# CH583SFR register map
Vendor: WCH Ltd.; Series: CH58x; File version: 1.1
CPU: RISC-V r0p0, little endian, no MPU, no FPU, 2 interrupt priority bits
Registers are 8-bit, read-write, reset 0x0 unless marked. A register's access mark holds for its fields unless they carry their own. Offsets are from the block's base; [hi:lo] are bit positions; {n}, {i} and the like mark numbered series.

## SYS — System Control Register
Base 0x40001000
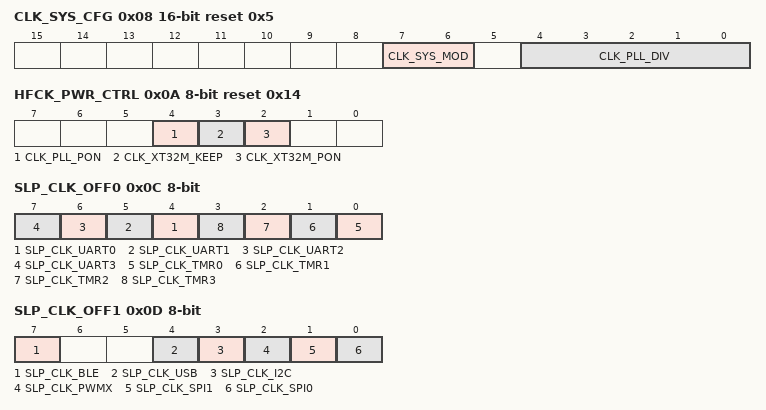
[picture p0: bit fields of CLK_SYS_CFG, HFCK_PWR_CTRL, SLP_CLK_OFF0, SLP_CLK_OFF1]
0x08 CLK_SYS_CFG 16-bit reset 0x5 — RWA, system clock configuration, SAM
  [7:6] CLK_SYS_MOD — RWA, system clock source mode: 00=divided from 32MHz, 01=divided from PLL-480MHz, 10=directly from 32MHz, 11=directly from 32KHz
  [4:0] CLK_PLL_DIV — RWA, output clock divider from PLL or CK32M
0x0A HFCK_PWR_CTRL reset 0x14 — RWA, high frequency clock module power control, SAM
  [4] CLK_PLL_PON — RWA, PLL power control: 0=power down, 1-power on
  [3] CLK_XT32M_KEEP — RWA, external 32MHz oscillator power keep under halt mode: 0=auto stop, 1=keep running
  [2] CLK_XT32M_PON — RWA, external 32MHz oscillator power control: 0=power down, 1-power on
0x0C SLP_CLK_OFF0 — RWA, sleep clock off control byte 0, SAM
  [n+4] SLP_CLK_UART{n} (n=0..3) — RWA, close UART{n} clock
  [n] SLP_CLK_TMR{n} (n=0..3) — RWA, close TMR{n} clock
0x0D SLP_CLK_OFF1 — RWA, sleep clock off control byte 1, SAM
  [7] SLP_CLK_BLE — RWA, close BLE clock
  [4] SLP_CLK_USB — RWA, close USB clock
  [3] SLP_CLK_I2C — RWA, close I2C clock
  [2] SLP_CLK_PWMX — RWA, close PWMx clock
  [1] SLP_CLK_SPI1 — RWA, close SPI1 clock
  [0] SLP_CLK_SPI0 — RWA, close SPI0 clock
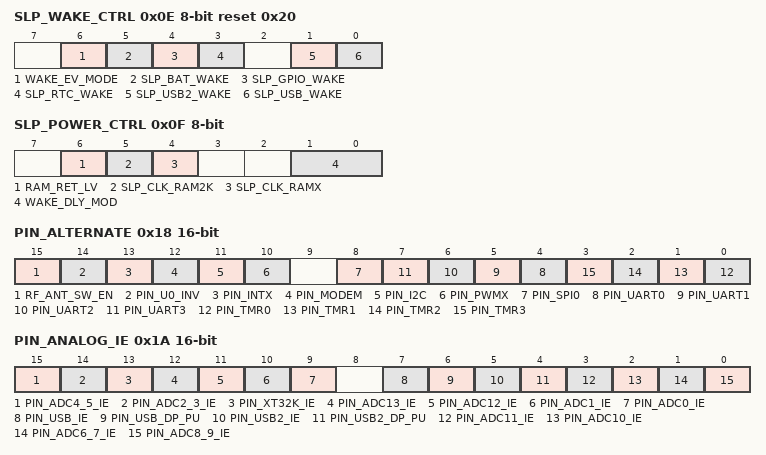
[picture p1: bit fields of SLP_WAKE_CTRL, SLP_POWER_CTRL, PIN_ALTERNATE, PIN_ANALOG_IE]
0x0E SLP_WAKE_CTRL reset 0x20 — RWA, wake control, SAM
  [6] WAKE_EV_MODE — RWA, event wakeup mode
  [5] SLP_BAT_WAKE — RWA, enable BAT waking
  [4] SLP_GPIO_WAKE — RWA, enable GPIO waking
  [3] SLP_RTC_WAKE — RWA, enable RTC waking
  [1] SLP_USB2_WAKE — RWA, enable USB2 waking
  [0] SLP_USB_WAKE — RWA, enable USB waking
0x0F SLP_POWER_CTRL — RWA, peripherals power down control, SAM
  [6] RAM_RET_LV — RWA, SRAM retention voltage selection
  [5] SLP_CLK_RAM2K — RWA, close retention 2KB SRAM clock
  [4] SLP_CLK_RAMX — RWA, close main SRAM clock
  [1:0] WAKE_DLY_MOD — RWA, wakeup delay time selection
0x18 PIN_ALTERNATE 16-bit — RW, function pin alternate configuration
  [15] RF_ANT_SW_EN — RW, RF antenna switch control output enable
  [14] PIN_U0_INV — RW, SCL/SDA alternRW, RXD0/RXD0_/TXD0/TXD0_ invert input/output enableate pin enable
  [13] PIN_INTX — RW, interrupt INT24/INT25 alternate pin enable
  [12] PIN_MODEM — RW, DSR/DTR alternate pin enable
  [11] PIN_I2C — RW, SCL/SDA alternate pin enable
  [10] PIN_PWMX — RW, PWM4/PWM5/PWM7/PWM8/PWM9 alternate pin enable
  [8] PIN_SPI0 — RW, SCS/SCK0/MOSI/MISO alternate pin enable
  [n+4] PIN_UART{n} (n=0..3) — RW, RXD{n}/TXD{n} alternate pin enable
  [n] PIN_TMR{n} (n=0..3) — RW, TMR{n} alternate pin enable
0x1A PIN_ANALOG_IE 16-bit — RW, analog pin enable and digital input disable
  [15] PIN_ADC4_5_IE — RW, ADC/TouchKey channel 4/5 digital input disable: 0=digital input enable, 1=digital input disable
  [14] PIN_ADC2_3_IE — RW, ADC/TouchKey channel 2/3 digital input disable: 0=digital input enable, 1=digital input disable
  [13] PIN_XT32K_IE — RW, external 32KHz oscillator digital input disable: 0=digital input enable, 1=digital input disable
  [12] PIN_ADC13_IE — RW, ADC/TouchKey channel13 digital input disable: 0=digital input enable, 1=digital input disable
  [11] PIN_ADC12_IE — RW, ADC/TouchKey channel12 digital input disable: 0=digital input enable, 1=digital input disable
  [10] PIN_ADC1_IE — RW, ADC/TouchKey channel1 digital input disable: 0=digital input enable, 1=digital input disable
  [9] PIN_ADC0_IE — RW, ADC/TouchKey channel0 digital input disable: 0=digital input enable, 1=digital input disable
  [7] PIN_USB_IE — RW, USB analog I/O enable: 0=analog I/O disable, 1=analog I/O enable
  [6] PIN_USB_DP_PU — RW,USB UDP internal pullup resistance enable
  [5] PIN_USB2_IE — RW, USB analog I/O enable: 0=analog I/O disable, 1=analog I/O enable
  [4] PIN_USB2_DP_PU — RW,USB2 UDP internal pullup resistance enable
  [3] PIN_ADC11_IE — RW, ADC/TouchKey channel 11 digital input disable
  [2] PIN_ADC10_IE — RW, ADC/TouchKey channel 10 digital input disable
  [1] PIN_ADC6_7_IE — RW, ADC/TouchKey channel 7/6 digital input disable
  [0] PIN_ADC8_9_IE — RW, ADC/TouchKey channel 9/8 digital input disable
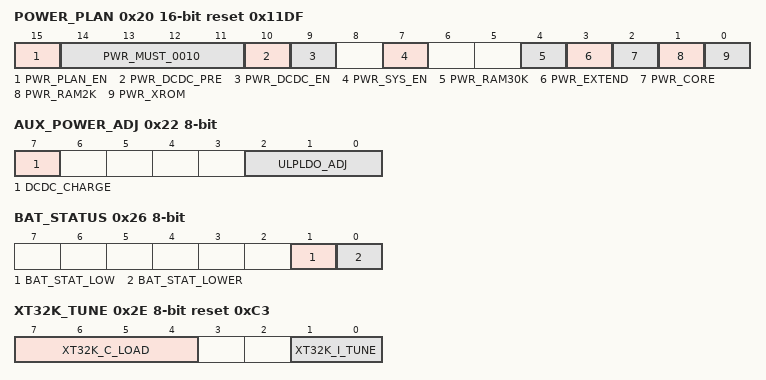
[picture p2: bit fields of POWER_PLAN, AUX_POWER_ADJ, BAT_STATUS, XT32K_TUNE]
0x20 POWER_PLAN 16-bit reset 0x11DF — RWA, power plan before sleep instruction, SAM
  [15] PWR_PLAN_EN ro — RWA, must write 0010
  [14:11] PWR_MUST_0010 ro — RWA, power plan enable, auto clear after sleep executed
  [10] PWR_DCDC_PRE — RWA, DC/DC converter pre-enable
  [9] PWR_DCDC_EN — RWA, DC/DC converter enable: 0=DC/DC disable and bypass, 1=DC/DC enable
  [7] PWR_SYS_EN — RWA, power for system
  [4] PWR_RAM30K — RWA, power for main SRAM
  [3] PWR_EXTEND — RWA, power retention for USB and BLE
  [2] PWR_CORE — RWA, power retention for core and base peripherals
  [1] PWR_RAM2K — RWA, power for retention 2KB SRAM
  [0] PWR_XROM — RWA, power for retention 2KB SRAM
0x22 AUX_POWER_ADJ — RWA, aux power adjust control, SAM
  [7] DCDC_CHARGE — RWA, Ultra-Low-Power LDO voltage adjust
  [2:0] ULPLDO_ADJ — RWA, Ultra-Low-Power LDO voltage adjust
0x24 BAT_DET_CTRL — RWA, battery voltage detector control, SAM
  [3] BAT_LOW_IE — RWA, interrupt enable for battery low voltage
  [2] BAT_LOWER_IE — RWA, interrupt enable for battery lower voltage
  [1] BAT_MON_EN — RWA, battery voltage monitor enable under sleep mode
  [0] BAT_DET_EN — RWA, battery voltage detector enable/select monitor threshold voltage
  [0] BAT_LOW_VTHX — RWA, battery voltage detector enable/select monitor threshold voltage
0x25 BAT_DET_CFG reset 0x1 — RWA, battery voltage detector configuration, SAM
  [1:0] BAT_LOW_VTH — RWA, select threshold voltage of battery voltage low
0x26 BAT_STATUS ro — RO, battery status
  [1] BAT_STAT_LOW — RO, battery low voltage status, high action
  [0] BAT_STAT_LOWER — RO, battery lower voltage status, high action
0x2C INT32K_TUNE 16-bit reset 0x1011 — RWA, internal 32KHz oscillator tune control, SAM
  [12:0] INT32K_TUNE — RWA, internal 32KHz oscillator frequency tune
0x2E XT32K_TUNE reset 0xC3 — RWA, external 32KHz oscillator tune control, SAM
  [7:4] XT32K_C_LOAD — RWA, external 32KHz oscillator load capacitor tune: Cap = RB_XT32K_C_LOAD + 12pF
  [1:0] XT32K_I_TUNE — RWA, external 32KHz oscillator current tune: 00=75% current, 01=standard current, 10=150% current, 11=200% current
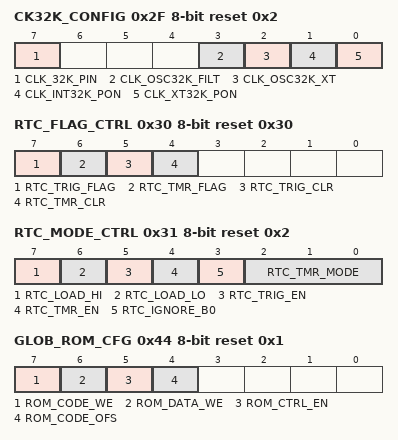
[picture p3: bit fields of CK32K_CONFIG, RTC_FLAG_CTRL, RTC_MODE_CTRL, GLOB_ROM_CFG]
0x2F CK32K_CONFIG reset 0x2 (reset mask 0xF) — RWA, 32KHz oscillator configure
  [7] CLK_32K_PIN ro — RO, 32KHz oscillator clock pin status
  [3] CLK_OSC32K_FILT — RWA, internal 32KHz oscillator low noise mode enable
  [2] CLK_OSC32K_XT — RWA, 32KHz oscillator source selection: 0=RC, 1=XT
  [1] CLK_INT32K_PON — RWA, internal 32KHz oscillator power on
  [0] CLK_XT32K_PON — RWA, external 32KHz oscillator power on
0x30 RTC_FLAG_CTRL reset 0x30 — RW, RTC flag and clear control
  [7] RTC_TRIG_FLAG ro — RO, RTC trigger action flag
  [6] RTC_TMR_FLAG ro — RO, RTC timer action flag
  [5] RTC_TRIG_CLR — RW, set 1 to clear RTC trigger action flag, auto clear
  [4] RTC_TMR_CLR — RW, set 1 to clear RTC timer action flag, auto clear
0x31 RTC_MODE_CTRL reset 0x2 — RWA, RTC mode control, SAM
  [7] RTC_LOAD_HI — RWA, set 1 to load RTC count high word R32_RTC_CNT_DAY, auto clear after loaded
  [6] RTC_LOAD_LO — RWA, set 1 to load RTC count low word R32_RTC_CNT_32K, auto clear after loaded
  [5] RTC_TRIG_EN — RWA, RTC trigger mode enable
  [4] RTC_TMR_EN — RWA, RTC timer mode enable
  [3] RTC_IGNORE_B0 — RWA, force ignore bit0 for trigger mode: 0=compare bit0, 1=ignore bit0
  [2:0] RTC_TMR_MODE — RWA, RTC timer mode: 000=0.125S, 001=0.25S, 010=0.5S, 011=1S, 100=2S, 101=4S, 110=8S, 111=16S
0x34 RTC_TRIG 32-bit — RWA, RTC trigger value, SAM
  [31:0] RTC_TRIG — RWA, RTC trigger value
0x38 RTC_CNT_32K 16-bit ro — RO, RTC count based 32KHz
  [15:0] RTC_CNT_32K — RWA,RTC count based 32KHz
0x3A RTC_CNT_2S 16-bit ro — RO, RTC count based 2 second
0x3C RTC_CNT_DAY 32-bit ro — RO, RTC count based one day, only low 14 bit
  [13:0] RTC_CNT_DAY — RWA,RTC count based one day
0x40 SAFE_ACCESS_SIG — WO, safe accessing sign register, must write SAFE_ACCESS_SIG1 then SAFE_ACCESS_SIG2 to enter safe accessing mode
  [6:4] SAFE_ACC_TIMER — RO, safe accessing timer bit mask (16*clock number)
  [3] SAFE_ACC_ACT — RO, indicate safe accessing status now: 0=locked, read only, 1=safe/unlocked (SAM), write enabled
  [1:0] SAFE_ACC_MODE — RO, current safe accessing mode: 11=safe unlocked (SAM), other=locked (00..01..10..11)
  [7:0] SAFE_ACCESS_SIG — WO, safe accessing sign register, must write 0x57 then 0xA8 to enter safe accessing mode
0x41 CHIP_ID ro reset 0x83 — RF, chip ID register, always is ID_CH58*
  [7:0] CHIP_ID — RF,chip ID register
0x42 SAFE_ACCESS_ID ro reset 0xC — RF, safe accessing ID register, always 0x0C
  [7:0] SAFE_ACCESS_ID — RF,safe accessing ID register
0x43 WDOG_COUNT — RW, watch-dog count, count by clock frequency Fsys/131072
  [7:0] WDOG_COUNT — RF,watch-dog count, count by clock frequency Fsys/131072
0x44 RESET_STATUS ro reset 0x1 — RWA, reset status
  [2:0] RESET_FLAG — RO, recent reset flag
0x44 GLOB_ROM_CFG ro reset 0x1 — RWA, flash ROM configuration
  [7] ROM_CODE_WE rw — RWA, enable flash ROM code area being erase or write
  [6] ROM_DATA_WE rw — RWA,enable flash ROM data and code area being erase/write
  [5] ROM_CTRL_EN rw — RWA, enable flash ROM control interface enable
  [4] ROM_CODE_OFS rw — RWA, code offset address selection in Flash ROM: 0=start address 0x000000, 1=start address 0x008000
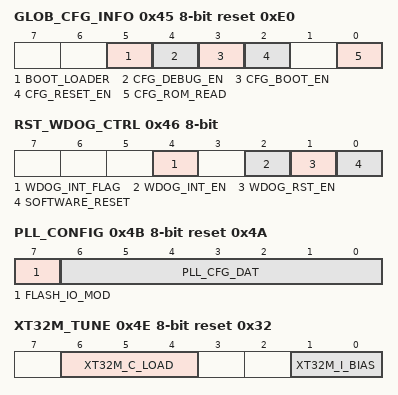
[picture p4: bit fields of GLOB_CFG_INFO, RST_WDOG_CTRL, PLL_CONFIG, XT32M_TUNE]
0x45 GLOB_CFG_INFO ro reset 0xE0 (reset mask 0xF0) — RO, global configuration information and status
  [5] BOOT_LOADER — RO, indicate boot loader status: 0=application status (by software reset), 1=boot loader status
  [4] CFG_DEBUG_EN — RO, debug enable status
  [3] CFG_BOOT_EN — RO, boot-loader enable status
  [2] CFG_RESET_EN — RO, manual reset input enable status
  [0] CFG_ROM_READ — RO, indicate protected status of Flash ROM code and data: 0=reading protect, 1=enable read by external programmer
0x46 RST_WDOG_CTRL — RWA, reset and watch-dog control, SAM
  [4] WDOG_INT_FLAG — RW1, watch-dog timer overflow interrupt flag, cleared by RW1 or reload watch-dog count or __SEV(Send-Event)
  [2] WDOG_INT_EN — RWA, watch-dog timer overflow interrupt enable: 0=disable, 1=enable
  [1] WDOG_RST_EN — RWA, enable watch-dog reset if watch-dog timer overflow: 0=as timer only, 1=enable reset if timer overflow
  [0] SOFTWARE_RESET — WA or WZ, global software reset, high action, auto clear
0x47 GLOB_RESET_KEEP — RW, value keeper during global reset
0x4B PLL_CONFIG reset 0x4A — RWA, PLL configuration control, SAM
  [7] FLASH_IO_MOD — RWA, flash ROM interface mode
  [6:0] PLL_CFG_DAT — RWA, PLL configure data
0x4E XT32M_TUNE reset 0x32 — RWA, external 32MHz oscillator tune control, SAM
  [6:4] XT32M_C_LOAD — RWA, external 32MHz oscillator load capacitor tune: Cap = RB_XT32M_C_LOAD * 2 + 10pF
  [1:0] XT32M_I_BIAS — RWA, external 32MHz oscillator bias current tune: 00=75% current, 01=standard current, 10=125% current, 11=150% current
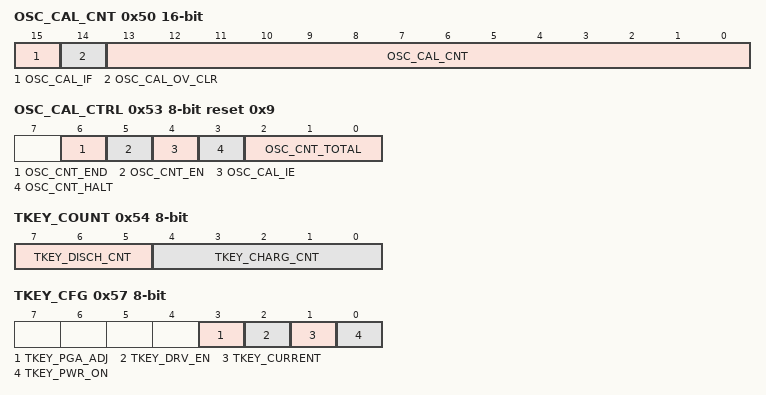
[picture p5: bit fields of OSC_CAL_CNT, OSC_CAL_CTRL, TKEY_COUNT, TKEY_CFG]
0x50 OSC_CAL_CNT 16-bit — RO, system clock count value for 32KHz multi-cycles
  [15] OSC_CAL_IF — RW1, interrupt flag for oscillator capture end, set 1 to clear
  [14] OSC_CAL_OV_CLR — RW1, indicate R8_OSC_CAL_OV_CNT not zero, set 1 to clear R8_OSC_CAL_OV_CNT
  [13:0] OSC_CAL_CNT — RO, system clock count value for 32KHz multi-cycles
0x52 OSC_CAL_OV_CNT ro — RO, oscillator frequency calibration overflow times
0x53 OSC_CAL_CTRL reset 0x9 — RWA, oscillator frequency calibration control, SAM
  [6] OSC_CNT_END — RWA, select oscillator capture end mode: 0=normal, 1=append 2 cycles
  [5] OSC_CNT_EN — RWA, calibration counter enable
  [4] OSC_CAL_IE — RWA, interrupt enable for oscillator capture end
  [3] OSC_CNT_HALT ro — RO, calibration counter halt status: 0=counting, 1=halt for reading count value
  [2:0] OSC_CNT_TOTAL — RWA, total cycles mode for oscillator capture
0x54 TKEY_COUNT — RW, Touchkey charge and discharge count
  [7:5] TKEY_DISCH_CNT — RW, Touchkey discharge count
  [4:0] TKEY_CHARG_CNT — RW, Touchkey charge count
0x56 TKEY_CONVERT — RW, Touchkey convert start control
  [0] TKEY_START
0x57 TKEY_CFG — RW, Touchkey configure
  [3] TKEY_PGA_ADJ — RW, ADC input PGA speed selection
  [2] TKEY_DRV_EN — RW, Touchkey drive shield enable
  [1] TKEY_CURRENT — RW, Touchkey charge current selection
  [0] TKEY_PWR_ON — RW, Touchkey power on
0x807 FLASH_CFG — Flash configuration
